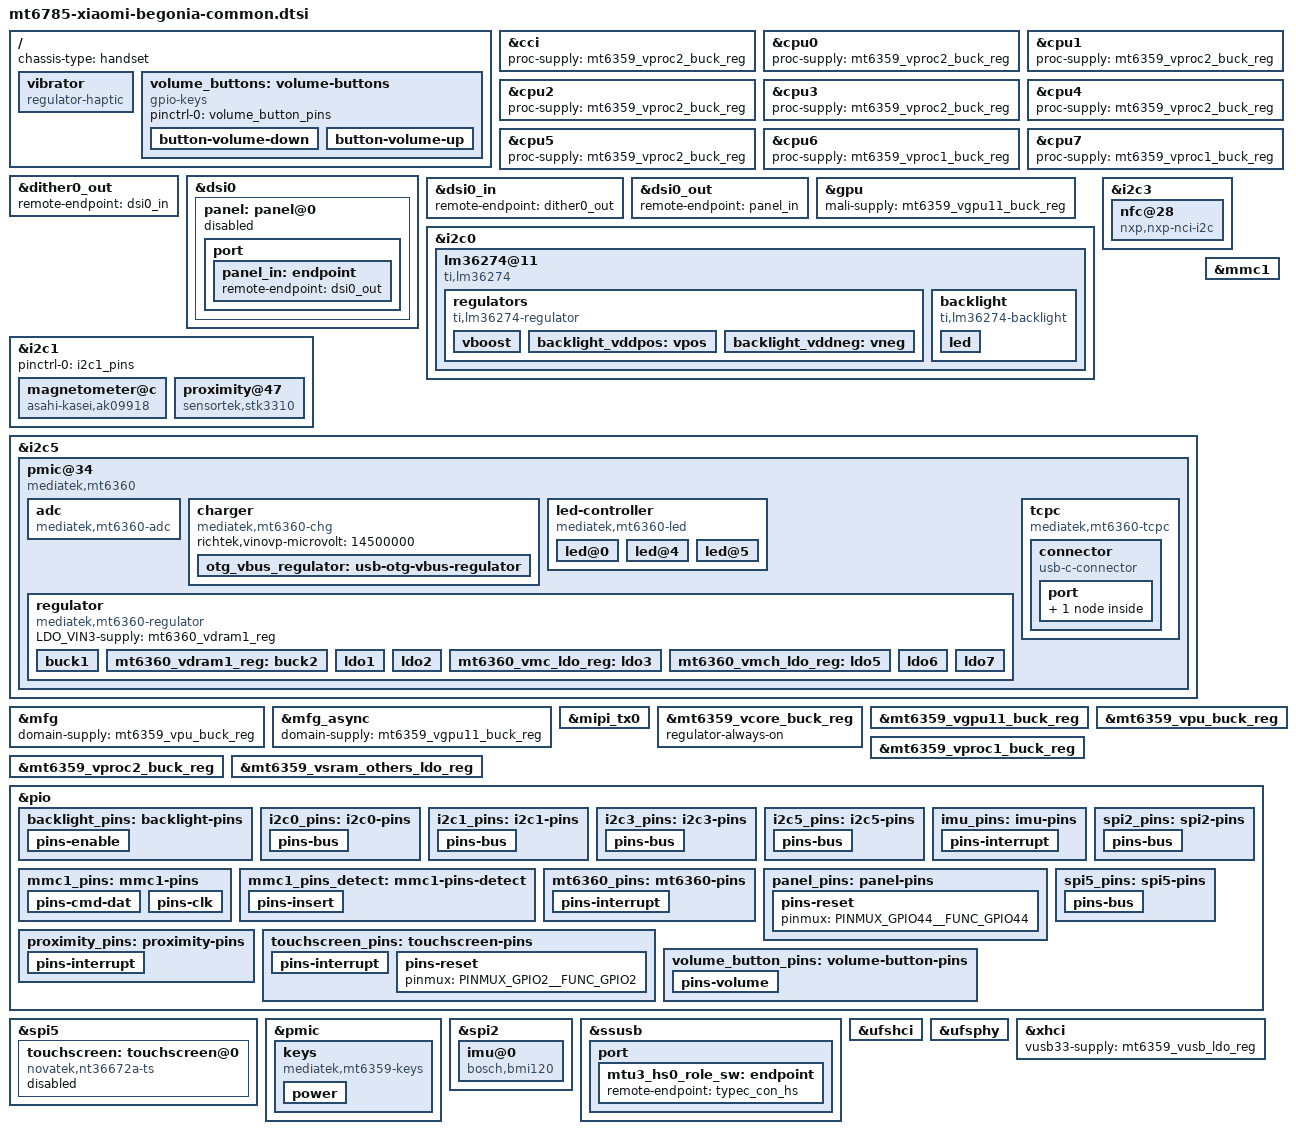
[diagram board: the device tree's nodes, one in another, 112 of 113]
// SPDX-License-Identifier: (GPL-2.0 OR MIT)
/*
 * Copyright (c) 2025 Dinolek <git@dinolek.me>
 */

#include <dt-bindings/gpio/gpio.h>
#include <dt-bindings/input/input.h>
#include <dt-bindings/leds/common.h>
#include <dt-bindings/regulator/mediatek,mt6360-regulator.h>
#include <dt-bindings/usb/pd.h>

#include "mt6785.dtsi"
#include "mt6359.dtsi"

/ {
	chassis-type = "handset";

	vibrator {
		compatible = "regulator-haptic";
		haptic-supply = <&mt6359_vibr_ldo_reg>;
		max-microvolt = <2800000>;
		min-microvolt = <1200000>;
	};

	volume_buttons: volume-buttons {
		compatible = "gpio-keys";
		pinctrl-names = "default";
		pinctrl-0 = <&volume_button_pins>;

		button-volume-down {
			label = "Volume Down";
			linux,code = <KEY_VOLUMEDOWN>;
			debounce-interval = <100>;

			gpios = <&pio 60 GPIO_ACTIVE_LOW>;
		};

		button-volume-up {
			label = "Volume Up";
			linux,code = <KEY_VOLUMEUP>;
			debounce-interval = <100>;

			gpios = <&pio 59 GPIO_ACTIVE_LOW>;
		};
	};
};

&cci {
	proc-supply = <&mt6359_vproc2_buck_reg>;
};

&cpu0 {
	proc-supply = <&mt6359_vproc2_buck_reg>;
};

&cpu1 {
	proc-supply = <&mt6359_vproc2_buck_reg>;
};

&cpu2 {
	proc-supply = <&mt6359_vproc2_buck_reg>;
};

&cpu3 {
	proc-supply = <&mt6359_vproc2_buck_reg>;
};

&cpu4 {
	proc-supply = <&mt6359_vproc2_buck_reg>;
};

&cpu5 {
	proc-supply = <&mt6359_vproc2_buck_reg>;
};

&cpu6 {
	proc-supply = <&mt6359_vproc1_buck_reg>;
};

&cpu7 {
	proc-supply = <&mt6359_vproc1_buck_reg>;
};

&dither0_out {
	remote-endpoint = <&dsi0_in>;
};

&dsi0 {
	status = "okay";

	panel: panel@0 {
		reg = <0>;

		backlight = <&backlight>;
		reset-gpios = <&pio 44 GPIO_ACTIVE_LOW>;

		vddio-supply = <&mt6359_vio18_ldo_reg>;
		vddneg-supply = <&backlight_vddpos>;
		vddpos-supply = <&backlight_vddneg>;

		pinctrl-names = "default";
		pinctrl-0 = <&panel_pins>;

		status = "disabled";

		port {
			panel_in: endpoint {
				remote-endpoint = <&dsi0_out>;
			};
		};
	};
};

&dsi0_in {
	remote-endpoint = <&dither0_out>;
};

&dsi0_out {
	remote-endpoint = <&panel_in>;
};

&gpu {
	mali-supply = <&mt6359_vgpu11_buck_reg>;
	status = "okay";
};

&i2c0 {
	clock-frequency = <400000>;

	pinctrl-names = "default";
	pinctrl-0 = <&i2c0_pins>;

	status = "okay";

	lm36274@11 {
		compatible = "ti,lm36274";
		reg = <0x11>;

		enable-gpios = <&pio 22 GPIO_ACTIVE_HIGH>;

		pinctrl-names = "default";
		pinctrl-0 = <&backlight_pins>;

		regulators {
			compatible = "ti,lm36274-regulator";

			vboost {
				regulator-name = "backlight_vboost";
				regulator-max-microvolt = <7150000>;
				regulator-min-microvolt = <4000000>;
				regulator-always-on;
			};

			backlight_vddpos: vpos {
				regulator-name = "backlight_vddpos";
				regulator-max-microvolt = <6500000>;
				regulator-min-microvolt = <4000000>;
			};

			backlight_vddneg: vneg {
				regulator-name = "backlight_vddneg";
				regulator-max-microvolt = <6500000>;
				regulator-min-microvolt = <4000000>;
			};
		};

		backlight: backlight {
			compatible = "ti,lm36274-backlight";

			led {
				default-brightness = <800>;
				led-sources = <0 1 2>;
				max-brightness = <1879>;
				ti,exponential-mode;
				ti,ovp-microvolt = <29000000>;
				ti,ramp-time-us = <100000>;
			};
		};
	};
};

&i2c1 {
	pinctrl-names = "default";
	pinctrl-0 = <&i2c1_pins>;

	status = "okay";

	magnetometer@c {
		compatible = "asahi-kasei,ak09918";
		reg = <0x0c>;

		vdd-supply = <&mt6359_vio18_ldo_reg>;
	};

	proximity@47 {
		compatible = "sensortek,stk3310";
		reg = <0x47>;

		interrupts-extended = <&pio 6 IRQ_TYPE_EDGE_FALLING>;
		proximity-near-level = <70>;

		pinctrl-names = "default";
		pinctrl-0 = <&proximity_pins>;
	};
};

&i2c3 {
	clock-frequency = <400000>;

	pinctrl-names = "default";
	pinctrl-0 = <&i2c3_pins>;

	status = "okay";

	nfc@28 {
		compatible = "nxp,nxp-nci-i2c";
		reg = <0x28>;

		interrupts-extended = <&pio 88 IRQ_TYPE_EDGE_FALLING>;

		enable-gpios = <&pio 168 GPIO_ACTIVE_HIGH>;
		firmware-gpios = <&pio 87 GPIO_ACTIVE_HIGH>;
	};
};

&i2c5 {
	clock-frequency = <3400000>;

	pinctrl-names = "default";
	pinctrl-0 = <&i2c5_pins>;

	status = "okay";

	pmic@34 {
		compatible = "mediatek,mt6360";
		reg = <0x34>;

		interrupts-extended = <&pio 16 IRQ_TYPE_EDGE_FALLING>;
		interrupt-names = "IRQB";
		interrupt-controller;
		#interrupt-cells = <1>;

		pinctrl-names = "default";
		pinctrl-0 = <&mt6360_pins>;

		adc {
			compatible = "mediatek,mt6360-adc";
			#io-channel-cells = <1>;
		};

		charger {
			compatible = "mediatek,mt6360-chg";
			richtek,vinovp-microvolt = <14500000>;

			otg_vbus_regulator: usb-otg-vbus-regulator {
				regulator-name = "usb-otg-vbus";
				regulator-max-microvolt = <5825000>;
				regulator-min-microvolt = <4425000>;
			};
		};

		led-controller {
			compatible = "mediatek,mt6360-led";

			#address-cells = <1>;
			#size-cells = <0>;

			led@0 {
				reg = <0>;
				color = <LED_COLOR_ID_WHITE>;
				function = LED_FUNCTION_INDICATOR;
				led-max-microamp = <24000>;
			};

			led@4 {
				reg = <4>;
				color = <LED_COLOR_ID_WHITE>;
				flash-max-microamp = <500000>;
				flash-max-timeout-us = <1024000>;
				function = LED_FUNCTION_FLASH;
				function-enumerator = <1>;
				led-max-microamp = <200000>;
			};

			led@5 {
				reg = <5>;
				color = <LED_COLOR_ID_WHITE>;
				flash-max-microamp = <500000>;
				flash-max-timeout-us = <1024000>;
				function = LED_FUNCTION_FLASH;
				function-enumerator = <2>;
				led-max-microamp = <200000>;
			};
		};

		regulator {
			compatible = "mediatek,mt6360-regulator";
			LDO_VIN3-supply = <&mt6360_vdram1_reg>;

			buck1 {
				regulator-name = "vapu";
				regulator-min-microvolt = <300000>;
				regulator-max-microvolt = <1300000>;
				regulator-allowed-modes = <MT6360_OPMODE_NORMAL
							   MT6360_OPMODE_LP
							   MT6360_OPMODE_ULP>;
			};

			mt6360_vdram1_reg: buck2 {
				regulator-name = "vdram1";
				regulator-min-microvolt = <300000>;
				regulator-max-microvolt = <1300000>;
				regulator-allowed-modes = <MT6360_OPMODE_NORMAL
							   MT6360_OPMODE_LP
							   MT6360_OPMODE_ULP>;
			};

			ldo1 {
				regulator-name = "vfp";
				regulator-min-microvolt = <1200000>;
				regulator-max-microvolt = <3600000>;
				regulator-allowed-modes = <MT6360_OPMODE_NORMAL
							   MT6360_OPMODE_LP>;
			};

			ldo2 {
				regulator-name = "vtp";
				regulator-min-microvolt = <1200000>;
				regulator-max-microvolt = <3600000>;
				regulator-allowed-modes = <MT6360_OPMODE_NORMAL
							   MT6360_OPMODE_LP>;
			};

			mt6360_vmc_ldo_reg: ldo3 {
				regulator-name = "vmc";
				regulator-min-microvolt = <1200000>;
				regulator-max-microvolt = <3600000>;
				regulator-allowed-modes = <MT6360_OPMODE_NORMAL
							   MT6360_OPMODE_LP>;
			};

			mt6360_vmch_ldo_reg: ldo5 {
				regulator-name = "vmch";
				regulator-min-microvolt = <2700000>;
				regulator-max-microvolt = <3600000>;
				regulator-allowed-modes = <MT6360_OPMODE_NORMAL
							   MT6360_OPMODE_LP>;
			};

			ldo6 {
				regulator-name = "vmddr";
				regulator-min-microvolt = <500000>;
				regulator-max-microvolt = <2100000>;
				regulator-allowed-modes = <MT6360_OPMODE_NORMAL
							   MT6360_OPMODE_LP>;
				regulator-always-on;
			};

			ldo7 {
				regulator-name = "vdram2";
				regulator-min-microvolt = <500000>;
				regulator-max-microvolt = <2100000>;
				regulator-allowed-modes = <MT6360_OPMODE_NORMAL
							   MT6360_OPMODE_LP>;
				regulator-always-on;
			};
		};

		tcpc {
			compatible = "mediatek,mt6360-tcpc";

			interrupts-extended = <&pio 7 IRQ_TYPE_EDGE_FALLING>;
			interrupt-names = "PD_IRQB";
			vbus-supply = <&otg_vbus_regulator>;

			connector {
				compatible = "usb-c-connector";
				label = "USB-C";
				data-role = "dual";
				op-sink-microwatt = <10000000>;
				power-role = "dual";
				try-power-role = "sink";

				source-pdos = <PDO_FIXED(5000, 1500,
							 PDO_FIXED_DUAL_ROLE |
							 PDO_FIXED_DATA_SWAP)>;
				sink-pdos = <PDO_FIXED(5000, 2000,
						       PDO_FIXED_DUAL_ROLE |
						       PDO_FIXED_DATA_SWAP)>;

				port {
					typec_con_hs: endpoint {
						remote-endpoint = <&mtu3_hs0_role_sw>;
					};
				};
			};
		};
	};
};

&mfg {
	domain-supply = <&mt6359_vpu_buck_reg>;
};

&mfg_async {
	domain-supply = <&mt6359_vgpu11_buck_reg>;
};

&mipi_tx0 {
	status = "okay";
};

&mmc1 {
	bus-width = <4>;
	cd-gpios = <&pio 8 GPIO_ACTIVE_HIGH>;
	max-frequency = <200000000>;

	cap-sd-highspeed;
	disable-wp;
	no-mmc;
	no-sdio;
	sd-uhs-ddr50;
	sd-uhs-sdr104;
	sd-uhs-sdr50;

	vmmc-supply = <&mt6360_vmch_ldo_reg>;
	vqmmc-supply = <&mt6360_vmc_ldo_reg>;

	pinctrl-names = "default", "state_uhs";
	pinctrl-0 = <&mmc1_pins>, <&mmc1_pins_detect>;
	pinctrl-1 = <&mmc1_pins>;

	status = "okay";
};

&mt6359_vcore_buck_reg {
	regulator-always-on;
};

&mt6359_vgpu11_buck_reg {
	regulator-name = "vgpu";
	regulator-min-microvolt = <550000>;
	regulator-max-microvolt = <875000>;

	regulator-coupled-with = <&mt6359_vpu_buck_reg>;
	regulator-coupled-max-spread = <100000>;
};

&mt6359_vproc1_buck_reg {
	regulator-name = "vproc_b";
	regulator-always-on;
};

&mt6359_vproc2_buck_reg {
	regulator-name = "vproc_l";
	regulator-always-on;
};

&mt6359_vpu_buck_reg {
	regulator-name = "vsram_gpu";
	regulator-min-microvolt = <850000>;
	regulator-max-microvolt = <975000>;

	regulator-coupled-with = <&mt6359_vgpu11_buck_reg>;
	regulator-coupled-max-spread = <100000>;
};

&mt6359_vsram_others_ldo_reg {
	regulator-name = "vsram_core";
	regulator-always-on;
};

&pio {
	backlight_pins: backlight-pins {
		pins-enable {
			pinmux = <PINMUX_GPIO22__FUNC_GPIO22>;
			output-high;
		};
	};

	i2c0_pins: i2c0-pins {
		pins-bus {
			pinmux = <PINMUX_GPIO51__FUNC_SCL0>,
				 <PINMUX_GPIO52__FUNC_SDA0>;
			bias-pull-up;
		};
	};

	i2c1_pins: i2c1-pins {
		pins-bus {
			pinmux = <PINMUX_GPIO61__FUNC_SCL1>,
				 <PINMUX_GPIO62__FUNC_SDA1>;
			bias-pull-up;
		};
	};

	i2c3_pins: i2c3-pins {
		pins-bus {
			pinmux = <PINMUX_GPIO55__FUNC_SCL3>,
				 <PINMUX_GPIO56__FUNC_SDA3>;
			bias-pull-up;
		};
	};

	i2c5_pins: i2c5-pins {
		pins-bus {
			pinmux = <PINMUX_GPIO28__FUNC_SCL5>,
				 <PINMUX_GPIO29__FUNC_SDA5>;
			bias-pull-up;
		};
	};

	imu_pins: imu-pins {
		pins-interrupt {
			pinmux = <PINMUX_GPIO10__FUNC_GPIO10>;
			bias-pull-down = <MTK_PUPD_SET_R1R0_00>;
			input-enable;
		};
	};

	mmc1_pins: mmc1-pins {
		pins-cmd-dat {
			pinmux = <PINMUX_GPIO135__FUNC_MSDC1_CMD>,
				 <PINMUX_GPIO137__FUNC_MSDC1_DAT0>,
				 <PINMUX_GPIO139__FUNC_MSDC1_DAT1>,
				 <PINMUX_GPIO138__FUNC_MSDC1_DAT2>,
				 <PINMUX_GPIO136__FUNC_MSDC1_DAT3>;
			bias-pull-up = <MTK_PUPD_SET_R1R0_01>;
			drive-strength = <8>;
			input-enable;
		};

		pins-clk {
			pinmux = <PINMUX_GPIO134__FUNC_MSDC1_CLK>;
			bias-pull-down = <MTK_PUPD_SET_R1R0_10>;
			drive-strength = <8>;
		};
	};

	mmc1_pins_detect: mmc1-pins-detect {
		pins-insert {
			pinmux = <PINMUX_GPIO8__FUNC_GPIO8>;
			bias-pull-up;
			input-enable;
		};
	};

	mt6360_pins: mt6360-pins {
		pins-interrupt {
			pinmux = <PINMUX_GPIO7__FUNC_GPIO7>,
				 <PINMUX_GPIO16__FUNC_GPIO16>;
			bias-pull-up;
			input-enable;
		};
	};

	panel_pins: panel-pins {
		pins-reset {
			pinmux = <PINMUX_GPIO44__FUNC_GPIO44>;
		};
	};

	proximity_pins: proximity-pins {
		pins-interrupt {
			pinmux = <PINMUX_GPIO6__FUNC_GPIO6>;
			bias-pull-up;
			input-enable;
		};
	};

	spi2_pins: spi2-pins {
		pins-bus {
			pinmux = <PINMUX_GPIO63__FUNC_SPI2_MI>,
				 <PINMUX_GPIO64__FUNC_SPI2_CSB>,
				 <PINMUX_GPIO65__FUNC_SPI2_MO>,
				 <PINMUX_GPIO66__FUNC_SPI2_CLK>;
			bias-disable;
		};
	};

	spi5_pins: spi5-pins {
		pins-bus {
			pinmux = <PINMUX_GPIO37__FUNC_SPI5_A_MI>,
				 <PINMUX_GPIO36__FUNC_SPI5_A_CSB>,
				 <PINMUX_GPIO35__FUNC_SPI5_A_MO>,
				 <PINMUX_GPIO38__FUNC_SPI5_A_CLK>;
			bias-disable;
		};
	};

	touchscreen_pins: touchscreen-pins {
		pins-interrupt {
			pinmux = <PINMUX_GPIO1__FUNC_GPIO1>;
			bias-pull-up;
			input-enable;
		};

		pins-reset {
			pinmux = <PINMUX_GPIO2__FUNC_GPIO2>;
		};
	};

	volume_button_pins: volume-button-pins {
		pins-volume {
			pinmux = <PINMUX_GPIO59__FUNC_KPCOL0>,
				 <PINMUX_GPIO60__FUNC_KPCOL1>;
			input-enable;
		};
	};
};

&spi5 {
	mediatek,pad-select = <0>;

	pinctrl-names = "default";
	pinctrl-0 = <&spi5_pins>;

	status = "okay";

	touchscreen: touchscreen@0 {
		compatible = "novatek,nt36672a-ts";
		reg = <0>;

		interrupts-extended = <&pio 1 IRQ_TYPE_EDGE_RISING>;
		reset-gpios = <&pio 2 GPIO_ACTIVE_HIGH>;
		panel = <&panel>;

		spi-cs-setup-delay-ns = <20>;
		spi-max-frequency = <5000000>;

		pinctrl-names = "default";
		pinctrl-0 = <&touchscreen_pins>;

		status = "disabled";
	};
};

&pmic {
	interrupts-extended = <&pio 193 IRQ_TYPE_LEVEL_HIGH>;

	keys {
		compatible = "mediatek,mt6359-keys";

		power {
			linux,keycodes = <KEY_POWER>;
			wakeup-source;
		};
	};
};

&spi2 {
	mediatek,pad-select = <0>;

	pinctrl-names = "default";
	pinctrl-0 = <&spi2_pins>;

	status = "okay";

	imu@0 {
		compatible = "bosch,bmi120";
		reg = <0>;

		interrupts-extended = <&pio 10 IRQ_TYPE_EDGE_RISING>;
		interrupt-names = "INT1";

		spi-cs-setup-delay-ns = <1000000>;
		spi-max-frequency = <10000000>;

		vdd-supply = <&mt6359_vio18_ldo_reg>;
		vddio-supply = <&mt6359_vio18_ldo_reg>;

		pinctrl-names = "default";
		pinctrl-0 = <&imu_pins>;

		mount-matrix = "0", "1", "0",
			       "-1", "0", "0",
			       "0", "0", "1";
	};
};

&ssusb {
	maximum-speed = "high-speed";
	usb-role-switch;
	vusb33-supply = <&mt6359_vusb_ldo_reg>;
	status = "okay";

	port {
		mtu3_hs0_role_sw: endpoint {
			remote-endpoint = <&typec_con_hs>;
		};
	};
};

&ufshci {
	mediatek,ufs-disable-mcq;
	mediatek,ufs-support-va09;

	va09-supply = <&mt6359_va09_ldo_reg>;
	vcc-supply = <&mt6359_vemc_ldo_reg>;
	vccq2-supply = <&mt6359_vufs_ldo_reg>;

	status = "okay";
};

&ufsphy {
	status = "okay";
};

&xhci {
	vusb33-supply = <&mt6359_vusb_ldo_reg>;
	status = "okay";
};
